# nrf9230_cellcore register map
Vendor: Nordic Semiconductor; Series: nRF92; File version: 1
CPU: CM33 r0p4, little endian, MPU, FPU, 3 interrupt priority bits, 480 interrupts, 8 SAU regions
Registers are 32-bit, read-write, reset 0x0 unless marked. A register's access mark holds for its fields unless they carry their own. Offsets are from the block's base; [hi:lo] are bit positions; lines under a group give offsets from that group; {n}, {i} and the like mark numbered series; 'fields as' and 'values as' point back to an identical list.

## CELLCORELSPDCTRL_NS — Cellular core LSPD FSM control
Base 0x54018500; alternate view of PCGCS1_S
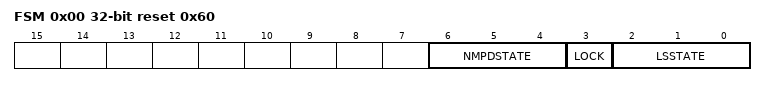
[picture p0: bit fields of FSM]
0x00 FSM reset 0x60 — Low speed power domain finite state machine control
  [6:4] NMPDSTATE — NMPDFSM state
    0=NMPD_PWR_UP (PD_TIMERS_ACT powering up state. Intermediate state before NMPD_PWR_ON.); 2=NMPD_PWR_ON_BCKD (PD_TIMERS_ACT powered. Unreachable state in normal use.); 3=NMPD_PWR_ON (PD_TIMERS_ACT powered. Normal operating state.); 4=NMPD_PWR_DOWN_DEL (PD_TIMERS_ACT powered. Preparing to power down the domain. Next state NMPD_PWR_DOWN.); 5=NMPD_PWR_DOWN (PD_TIMERS_ACT powering off. Waiting state to make sure domain ready to be powered off. Intermediate state before NMPD_PWR_OFF.); 6=NMPD_PWR_OFF (PD_TIMERS_ACT powered off.)
  [3] LOCK — Lock the state of LSPD FSMs.
    0=UNLOCKED (FSMs not locked.); 1=LOCKED (FSMs locked.)
  [2:0] LSSTATE — LSFSM state
    0=PWR_OFF_HSPD (Power requested for PD_MAIN, no constant clock request. PD_CORE_ACT power off.); 1=PWR_UP_HSPD (Clock and power requested for PD_MAIN. PD_CORE_ACT powering up. Intermediate state before PWR_ON_HSPD.); 2=PWR_ON_HSPD (Clock and power requested for PD_MAIN. PD_CORE_ACT powered.); 3=GUARD_HSPD_BRIDGE (Clock and power requested for PD_MAIN. PD_CORE_ACT powered, idle period to wait if new AXI transaction is coming.); 4=PWR_DOWN_HSPD (Clock and power requested for PD_MAIN. PD_CORE_ACT powering down. Intermediate state before PWR_OFF_HSPD.); 5=PWR_COMA_MCU (No power or clock requests for PD_MAIN. All domains powering down.)

## PPIB0_NS — PPIB APB registers 0
Base 0x4401A000
Same registers: PPIB1_NS 0x44026000, PPIB2_NS 0x44039000, PPIB0_S 0x5401A000, PPIB1_S 0x54026000, PPIB2_S 0x54039000
{0x0+4i} TASKS_SEND[{i}] (i=0..31) wo — Description collection: This task is unused, but the PPIB provides the SUBSCRIBE task to connect SEND [n] task.
  [0] TASKS_SEND — This task is unused, but the PPIB provides the SUBSCRIBE task to connect SEND [n] task.
    1=Trigger task
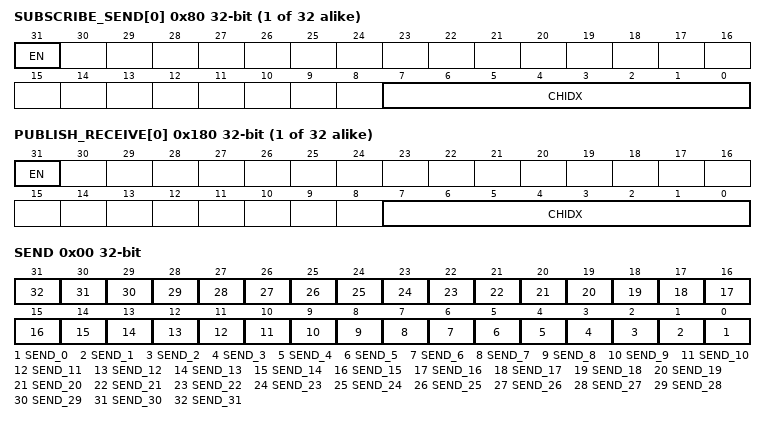
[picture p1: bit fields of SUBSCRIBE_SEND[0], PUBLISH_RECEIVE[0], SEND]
{0x80+4i} SUBSCRIBE_SEND[{i}] (i=0..31) — Description collection: Subscribe configuration for task SEND[n]
  [31] EN
    0=Disabled (Disable subscription); 1=Enabled (Enable subscription)
  [7:0] CHIDX — DPPI channel that task SEND[n] will subscribe to
{0x100+4i} EVENTS_RECEIVE[{i}] (i=0..31) — Description collection: This event is unused, but the PPIB provides the PUBLISH event to connect RECEIVE [n] event.
  [0] EVENTS_RECEIVE — This event is unused, but the PPIB provides the PUBLISH event to connect RECEIVE [n] event.
    0=NotGenerated (Event not generated); 1=Generated (Event generated)
{0x180+4i} PUBLISH_RECEIVE[{i}] (i=0..31) — Description collection: Publish configuration for event RECEIVE[n]
  [31] EN
    0=Disabled (Disable publishing); 1=Enabled (Enable publishing)
  [7:0] CHIDX — DPPI channel that event RECEIVE[n] will publish to
0x400 OVERFLOW group — Unspecified
  0x00 SEND — The task overflow for SEND tasks using SUBSCRIBE_SEND. Write 0 to clear.
    [all] fields
      1=Overflow (Task overflow is happened.); 0=NoOverflow (Task overflow is not happened.)
    [n] SEND_{n} (n=0..31) — The status for tasks overflow at SUBSCRIBE_SEND[{n}].

## DPPIC0_NS — Distributed programmable peripheral interconnect controller 0
Base 0x44021000
Same registers: DPPIC1_NS 0x44032000, GLOBAL_DPPIC120_NS 0x4F8E1000, GLOBAL_DPPIC130_NS 0x4F922000, GLOBAL_DPPIC131_NS 0x4F981000, GLOBAL_DPPIC132_NS 0x4F991000, GLOBAL_DPPIC133_NS 0x4F9A1000, GLOBAL_DPPIC134_NS 0x4F9B1000, GLOBAL_DPPIC135_NS 0x4F9C1000, GLOBAL_DPPIC136_NS 0x4F9D1000, DPPIC0_S 0x54021000, DPPIC1_S 0x54032000, GLOBAL_DPPIC120_S 0x5F8E1000, GLOBAL_DPPIC130_S 0x5F922000, GLOBAL_DPPIC131_S 0x5F981000, GLOBAL_DPPIC132_S 0x5F991000, GLOBAL_DPPIC133_S 0x5F9A1000, GLOBAL_DPPIC134_S 0x5F9B1000, GLOBAL_DPPIC135_S 0x5F9C1000, GLOBAL_DPPIC136_S 0x5F9D1000
{0x0+8i} TASKS_CHG[{i}] (i=0..3) group — Channel group tasks
  0x00 EN wo — Description cluster: Enable channel group n
    [0] EN — Enable channel group n
      1=Trigger task
  0x04 DIS wo — Description cluster: Disable channel group n
    [0] DIS — Disable channel group n
      1=Trigger task
{0x80+8i} SUBSCRIBE_CHG[{i}] (i=0..3) group — Subscribe configuration for tasks
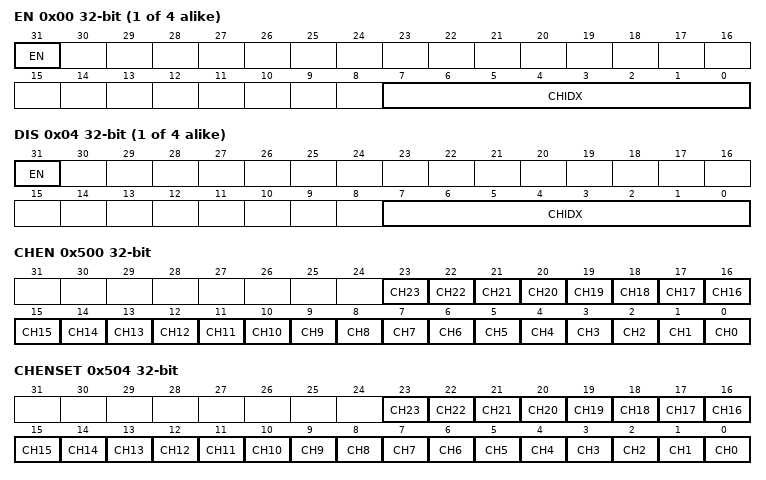
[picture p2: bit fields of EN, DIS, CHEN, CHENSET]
  0x00 EN — Description cluster: Subscribe configuration for task CHG[n].EN
    [31] EN
      0=Disabled (Disable subscription); 1=Enabled (Enable subscription)
    [7:0] CHIDX — DPPI channel that task CHG[n].EN will subscribe to
  0x04 DIS — Description cluster: Subscribe configuration for task CHG[n].DIS
    [31] EN
      values as SUBSCRIBE_CHG[0].EN.EN
    [7:0] CHIDX — DPPI channel that task CHG[n].DIS will subscribe to
0x500 CHEN — Channel enable register
  [all] fields
    0=Disabled (Disable channel); 1=Enabled (Enable channel)
  [n] CH{n} (n=0..23) — Enable or disable channel {n}
0x504 CHENSET write-1-sets — Channel enable set register
  [all] fields
    on read: 0=Disabled (Read: Channel disabled); 1=Enabled (Read: Channel enabled) | on write: 1=Set (Write: Enable channel)
  [n] CH{n} (n=0..23) — Channel {n} enable set register. Writing 0 has no effect.
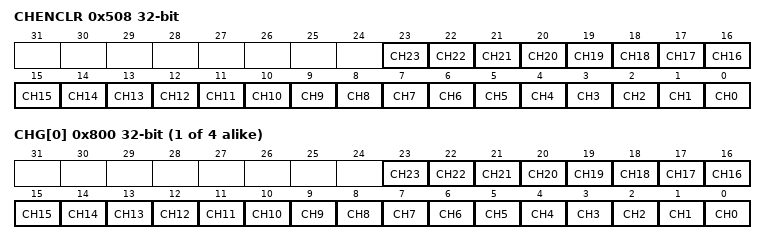
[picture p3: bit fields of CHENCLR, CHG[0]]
0x508 CHENCLR write-1-clears — Channel enable clear register
  [all] fields
    on read: 0=Disabled (Read: Channel disabled); 1=Enabled (Read: Channel enabled) | on write: 1=Clear (Write: Disable channel)
  [n] CH{n} (n=0..23) — Channel {n} enable clear register. Writing 0 has no effect.
{0x800+4i} CHG[{i}] (i=0..3) — Description collection: Channel group n Note: Writes to this register are ignored if either SUBSCRIBE_CHG[n].EN or SUBSCRIBE_CHG[n].DIS is enabled
  [all] fields
    0=Excluded; 1=Included
  [n] CH{n} (n=0..23) — Include or exclude channel {n}

## Notices in the file
Copyright (c) 2010 - 2024, Nordic Semiconductor ASA
All rights reserved.
Redistribution and use in source and binary forms, with or without modification,
are permitted provided that the following conditions are met:
1. Redistributions of source code must retain the above copyright notice, this
list of conditions and the following disclaimer.
2. Redistributions in binary form, except as embedded into a Nordic
Semiconductor ASA integrated circuit in a product or a software update for
such product, must reproduce the above copyright notice, this list of
conditions and the following disclaimer in the documentation and/or other
materials provided with the distribution.
3. Neither the name of Nordic Semiconductor ASA nor the names of its
contributors may be used to endorse or promote products derived from this
software without specific prior written permission.
4. This software, with or without modification, must only be used with a
Nordic Semiconductor ASA integrated circuit.
5. Any software provided in binary form under this license must not be reverse
engineered, decompiled, modified and/or disassembled.
THIS SOFTWARE IS PROVIDED BY NORDIC SEMICONDUCTOR ASA "AS IS" AND ANY EXPRESS
OR IMPLIED WARRANTIES, INCLUDING, BUT NOT LIMITED TO, THE IMPLIED WARRANTIES
OF MERCHANTABILITY, NONINFRINGEMENT, AND FITNESS FOR A PARTICULAR PURPOSE ARE
DISCLAIMED. IN NO EVENT SHALL NORDIC SEMICONDUCTOR ASA OR CONTRIBUTORS BE
LIABLE FOR ANY DIRECT, INDIRECT, INCIDENTAL, SPECIAL, EXEMPLARY, OR
CONSEQUENTIAL DAMAGES (INCLUDING, BUT NOT LIMITED TO, PROCUREMENT OF SUBSTITUTE
GOODS OR SERVICES; LOSS OF USE, DATA, OR PROFITS; OR BUSINESS INTERRUPTION)
HOWEVER CAUSED AND ON ANY THEORY OF LIABILITY, WHETHER IN CONTRACT, STRICT
LIABILITY, OR TORT (INCLUDING NEGLIGENCE OR OTHERWISE) ARISING IN ANY WAY OUT
OF THE USE OF THIS SOFTWARE, EVEN IF ADVISED OF THE POSSIBILITY OF SUCH DAMAGE.
